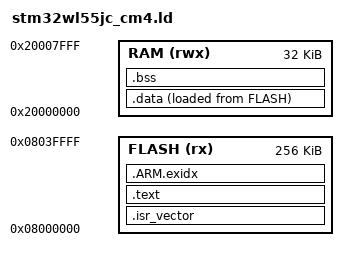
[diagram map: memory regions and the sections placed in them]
/* STM32WL55JC, CPU1 (Cortex-M4). Uses SRAM1 only; SRAM2 is left for CPU2. */
ENTRY(Reset_Handler)

MEMORY
{
    FLASH (rx)  : ORIGIN = 0x08000000, LENGTH = 256K
    RAM   (rwx) : ORIGIN = 0x20000000, LENGTH = 32K
}

_estack = ORIGIN(RAM) + LENGTH(RAM);

SECTIONS
{
    .isr_vector : { KEEP(*(.isr_vector)) } > FLASH

    .text :
    {
        *(.text*)
        *(.rodata*)
        . = ALIGN(4);
    } > FLASH

    .ARM.exidx : { *(.ARM.exidx*) } > FLASH

    _sidata = LOADADDR(.data);
    .data :
    {
        . = ALIGN(4);
        _sdata = .;
        *(.data*)
        . = ALIGN(4);
        _edata = .;
    } > RAM AT > FLASH

    .bss (NOLOAD) :
    {
        . = ALIGN(4);
        _sbss = .;
        *(.bss*)
        *(COMMON)
        . = ALIGN(4);
        _ebss = .;
    } > RAM

    /* fail the link if globals leave less than 4 KB for the stack */
    ASSERT(_ebss + 4096 <= _estack, "not enough RAM left for the stack")
}
